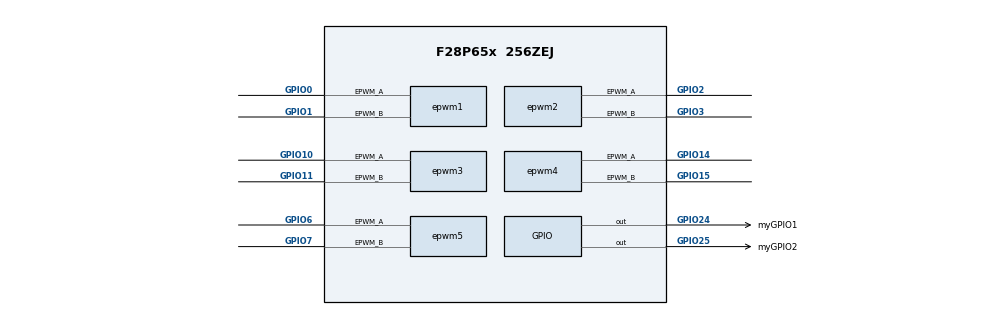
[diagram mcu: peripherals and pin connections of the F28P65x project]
/**
 * @cliArgs --device "F28P65x" --package "256ZEJ" --part "F28P65x_256ZEJ" --context "CPU1" --product "C2000WARE@5.00.00.00"
 * @versions {"tool":"1.17.0+3047"}
 */

/**
 * Import the modules used in this configuration.
 */
const epwm   = scripting.addModule("/driverlib/epwm.js", {}, false);
const epwm1  = epwm.addInstance();
const epwm2  = epwm.addInstance();
const epwm3  = epwm.addInstance();
const epwm4  = epwm.addInstance();
const epwm5  = epwm.addInstance();
const gpio   = scripting.addModule("/driverlib/gpio.js", {}, false);
const gpio1  = gpio.addInstance();
const gpio2  = gpio.addInstance();
const sysctl = scripting.addModule("/driverlib/sysctl.js");

/**
 * Write custom configuration values to the imported modules.
 */
epwm1.epwmTimebase_counterMode                                 = "EPWM_COUNTER_MODE_UP";
epwm1.epwmTimebase_syncOutPulseMode                            = ["EPWM_SYNC_OUT_PULSE_ON_ALL"];
epwm1.epwmActionQualifier_EPWM_AQ_OUTPUT_A_ON_TIMEBASE_UP_CMPA = "EPWM_AQ_OUTPUT_LOW";
epwm1.epwmTimebase_periodLoadMode                              = "EPWM_PERIOD_DIRECT_LOAD";
epwm1.epwmCounterCompare_shadowLoadModeCMPD                    = "EPWM_COMP_LOAD_ON_CNTR_PERIOD";
epwm1.hrpwm_edgeModeA                                          = "HRPWM_MEP_CTRL_RISING_EDGE";
epwm1.epwmXCMP_enable                                          = true;
epwm1.XCMPA_ACTIVE_OUTPUT_ON_TIMEBASE_XCMP1                    = "EPWM_AQ_OUTPUT_HIGH";
epwm1.XCMPA_ACTIVE_OUTPUT_ON_TIMEBASE_XCMP2                    = "EPWM_AQ_OUTPUT_LOW";
epwm1.epwmTimebase_period                                      = 1999;
epwm1.epwmXCMP_setRegisters_XTBPRD                             = 1999;
epwm1.epwmXCMP_selectAllocationXCMPA_NoSplitorSplit            = "EPWM_XCMP_8_CMPA";
epwm1.epwmXCMP_setXCMPA_XCMP3_ACTIVE                           = 500;
epwm1.epwmXCMP_setXCMPA_XCMP4_ACTIVE                           = 750;
epwm1.epwmXCMP_setXCMPA_XCMP5_ACTIVE                           = 1000;
epwm1.epwmXCMP_setXCMPA_XCMP6_ACTIVE                           = 1250;
epwm1.epwmXCMP_setXCMPA_XCMP7_ACTIVE                           = 1500;
epwm1.epwmXCMP_setXCMPA_XCMP8_ACTIVE                           = 1750;
epwm1.XCMPA_ACTIVE_OUTPUT_ON_TIMEBASE_XCMP3                    = "EPWM_AQ_OUTPUT_HIGH";
epwm1.XCMPA_ACTIVE_OUTPUT_ON_TIMEBASE_XCMP4                    = "EPWM_AQ_OUTPUT_LOW";
epwm1.XCMPA_ACTIVE_OUTPUT_ON_TIMEBASE_XCMP5                    = "EPWM_AQ_OUTPUT_HIGH";
epwm1.XCMPA_ACTIVE_OUTPUT_ON_TIMEBASE_XCMP6                    = "EPWM_AQ_OUTPUT_LOW";
epwm1.XCMPA_ACTIVE_OUTPUT_ON_TIMEBASE_XCMP7                    = "EPWM_AQ_OUTPUT_HIGH";
epwm1.XCMPA_ACTIVE_OUTPUT_ON_TIMEBASE_XCMP8                    = "EPWM_AQ_OUTPUT_LOW";
epwm1.epwmICL_A_OUTHIGH                                        = ["EPWM_MINDB_ICL_LUT_DEC0","EPWM_MINDB_ICL_LUT_DEC1","EPWM_MINDB_ICL_LUT_DEC2","EPWM_MINDB_ICL_LUT_DEC3"];
epwm1.epwmICL_A_OUTLOW                                         = ["EPWM_MINDB_ICL_LUT_DEC4","EPWM_MINDB_ICL_LUT_DEC5","EPWM_MINDB_ICL_LUT_DEC6","EPWM_MINDB_ICL_LUT_DEC7"];
epwm1.epwmTimebase_syncInPulseSource                           = "EPWM_SYNC_IN_PULSE_SRC_DISABLE";
epwm1.epwmCounterCompare_shadowLoadModeCMPC                    = "EPWM_COMP_LOAD_ON_CNTR_PERIOD";
epwm1.epwmXCMP_setXCMPA_XCMP2_ACTIVE                           = 250;
epwm1.$name                                                    = "myEPWM1";
epwm1.epwm.$assign                                             = "EPWM1";
epwm1.epwm.epwm_aPin.$assign                                   = "GPIO0";
epwm1.epwm.epwm_bPin.$assign                                   = "GPIO1";
scripting.suppress("When XCMP mode is enabled, EPWM Time Base Period will be set within XCMP Mode", epwm1, "epwmTimebase_period");

epwm2.copyFrom                                                 = "myEPWM0";
epwm2.epwmTimebase_periodLoadMode                              = "EPWM_PERIOD_DIRECT_LOAD";
epwm2.epwmTimebase_period                                      = 1999;
epwm2.epwmTimebase_counterMode                                 = "EPWM_COUNTER_MODE_UP";
epwm2.epwmTimebase_syncInPulseSource                           = "EPWM_SYNC_IN_PULSE_SRC_DISABLE";
epwm2.epwmTimebase_syncOutPulseMode                            = ["EPWM_SYNC_OUT_PULSE_ON_ALL"];
epwm2.epwmCounterCompare_shadowLoadModeCMPC                    = "EPWM_COMP_LOAD_ON_CNTR_PERIOD";
epwm2.epwmCounterCompare_shadowLoadModeCMPD                    = "EPWM_COMP_LOAD_ON_CNTR_PERIOD";
epwm2.epwmActionQualifier_EPWM_AQ_OUTPUT_A_ON_TIMEBASE_UP_CMPA = "EPWM_AQ_OUTPUT_LOW";
epwm2.epwmICL_A_OUTHIGH                                        = ["EPWM_MINDB_ICL_LUT_DEC0","EPWM_MINDB_ICL_LUT_DEC1","EPWM_MINDB_ICL_LUT_DEC2","EPWM_MINDB_ICL_LUT_DEC3"];
epwm2.epwmICL_A_OUTLOW                                         = ["EPWM_MINDB_ICL_LUT_DEC4","EPWM_MINDB_ICL_LUT_DEC5","EPWM_MINDB_ICL_LUT_DEC6","EPWM_MINDB_ICL_LUT_DEC7"];
epwm2.hrpwm_edgeModeA                                          = "HRPWM_MEP_CTRL_RISING_EDGE";
epwm2.epwmXCMP_enable                                          = true;
epwm2.epwmXCMP_RegisterSplit_enable                            = true;
epwm2.epwmXCMP_selectAllocationXCMPA_NoSplitorSplit            = "EPWM_XCMP_4_CMPA";
epwm2.epwmXCMP_setXCMPA_XCMP2_ACTIVE                           = 500;
epwm2.epwmXCMP_setXCMPA_XCMP4_ACTIVE                           = 1500;
epwm2.epwmXCMP_setXCMPA_XCMP3_ACTIVE                           = 1000;
epwm2.epwmXCMP_selectAllocationXCMPB_Split                     = "EPWM_XCMP_8_CMPB";
epwm2.epwmXCMP_setXCMPB_XCMP6_ACTIVE                           = 500;
epwm2.epwmXCMP_setXCMPB_XCMP7_ACTIVE                           = 1000;
epwm2.epwmXCMP_setXCMPB_XCMP8_ACTIVE                           = 1500;
epwm2.epwmXCMP_setRegisters_XTBPRD                             = 1999;
epwm2.XCMPA_ACTIVE_OUTPUT_ON_TIMEBASE_XCMP1                    = "EPWM_AQ_OUTPUT_HIGH";
epwm2.XCMPA_ACTIVE_OUTPUT_ON_TIMEBASE_XCMP2                    = "EPWM_AQ_OUTPUT_LOW";
epwm2.XCMPA_ACTIVE_OUTPUT_ON_TIMEBASE_XCMP3                    = "EPWM_AQ_OUTPUT_HIGH";
epwm2.XCMPA_ACTIVE_OUTPUT_ON_TIMEBASE_XCMP4                    = "EPWM_AQ_OUTPUT_LOW";
epwm2.XCMPB_ACTIVE_OUTPUT_ON_TIMEBASE_XCMP5                    = "EPWM_AQ_OUTPUT_LOW";
epwm2.XCMPB_ACTIVE_OUTPUT_ON_TIMEBASE_XCMP6                    = "EPWM_AQ_OUTPUT_HIGH";
epwm2.XCMPB_ACTIVE_OUTPUT_ON_TIMEBASE_XCMP7                    = "EPWM_AQ_OUTPUT_LOW";
epwm2.XCMPB_ACTIVE_OUTPUT_ON_TIMEBASE_XCMP8                    = "EPWM_AQ_OUTPUT_HIGH";
epwm2.$name                                                    = "myEPWM2";
epwm2.epwm.$assign                                             = "EPWM2";
epwm2.epwm.epwm_aPin.$assign                                   = "GPIO2";
epwm2.epwm.epwm_bPin.$assign                                   = "GPIO3";

epwm3.epwmTimebase_counterMode                        = "EPWM_COUNTER_MODE_UP";
epwm3.epwmTimebase_period                             = 1999;
epwm3.epwmTimebase_syncOutPulseMode                   = ["EPWM_SYNC_OUT_PULSE_ON_ALL"];
epwm3.epwmTimebase_syncInPulseSource                  = "EPWM_SYNC_IN_PULSE_SRC_DISABLE";
epwm3.epwmXCMP_enable                                 = true;
epwm3.epwmCounterCompare_shadowLoadModeCMPC           = "EPWM_COMP_LOAD_ON_CNTR_PERIOD";
epwm3.epwmCounterCompare_shadowLoadModeCMPD           = "EPWM_COMP_LOAD_ON_CNTR_PERIOD";
epwm3.epwmXCMP_selectNumberShadowRegisterLevels       = "EPWM_XCMP_XLOADCTL_SHDWLEVEL_3";
epwm3.epwmXCMP_selectLoadMode                         = "EPWM_XCMP_XLOADCTL_LOADMODE_LOADMULTIPLE";
epwm3.epwmXCMP_selectAllocationXCMPA_NoSplitorSplit   = "EPWM_XCMP_4_CMPA";
epwm3.epwmXCMP_selectRepeatCountShadowRegisterLevel3  = "4";
epwm3.epwmXCMP_selectRepeatCountShadowRegisterLevel2  = "2";
epwm3.epwmXCMP_setRegisters_XTBPRD                    = 1999;
epwm3.epwmXCMP_setXCMPA_XCMP2_SHADOW3                 = 500;
epwm3.epwmXCMP_setXCMPA_XCMP3_SHADOW3                 = 1000;
epwm3.epwmXCMP_setXCMPA_XCMP4_SHADOW3                 = 1500;
epwm3.epwmXCMP_setXCMPA_XCMP2_SHADOW2                 = 500;
epwm3.epwmXCMP_setXCMPA_XCMP3_SHADOW2                 = 1000;
epwm3.epwmXCMP_setXCMPA_XCMP4_SHADOW2                 = 1500;
epwm3.epwmXCMP_setXCMPA_XCMP2_SHADOW1                 = 500;
epwm3.epwmXCMP_setXCMPA_XCMP3_SHADOW1                 = 1000;
epwm3.epwmXCMP_setXCMPA_XCMP4_SHADOW1                 = 1500;
epwm3.XCMPA_SHADOW1_OUTPUT_ON_TIMEBASE_XCMP1          = "EPWM_AQ_OUTPUT_HIGH";
epwm3.XCMPA_SHADOW1_OUTPUT_ON_TIMEBASE_XCMP2          = "EPWM_AQ_OUTPUT_LOW";
epwm3.XCMPA_SHADOW1_OUTPUT_ON_TIMEBASE_XCMP3          = "EPWM_AQ_OUTPUT_HIGH";
epwm3.XCMPA_SHADOW1_OUTPUT_ON_TIMEBASE_XCMP4          = "EPWM_AQ_OUTPUT_LOW";
epwm3.XCMPA_SHADOW2_OUTPUT_ON_TIMEBASE_XCMP1          = "EPWM_AQ_OUTPUT_HIGH";
epwm3.XCMPA_SHADOW2_OUTPUT_ON_TIMEBASE_XCMP2          = "EPWM_AQ_OUTPUT_LOW";
epwm3.XCMPA_SHADOW2_OUTPUT_ON_TIMEBASE_XCMP3          = "EPWM_AQ_OUTPUT_HIGH";
epwm3.XCMPA_SHADOW2_OUTPUT_ON_TIMEBASE_XCMP4          = "EPWM_AQ_OUTPUT_LOW";
epwm3.XCMPA_SHADOW3_OUTPUT_ON_TIMEBASE_XCMP1          = "EPWM_AQ_OUTPUT_HIGH";
epwm3.XCMPA_SHADOW3_OUTPUT_ON_TIMEBASE_XCMP2          = "EPWM_AQ_OUTPUT_LOW";
epwm3.XCMPA_SHADOW3_OUTPUT_ON_TIMEBASE_XCMP3          = "EPWM_AQ_OUTPUT_HIGH";
epwm3.XCMPA_SHADOW3_OUTPUT_ON_TIMEBASE_XCMP4          = "EPWM_AQ_OUTPUT_LOW";
epwm3.epwmEventTrigger_enableInterrupt                = true;
epwm3.epwmEventTrigger_registerInterrupts             = true;
epwm3.epwmEventTrigger_interruptSource                = "EPWM_INT_TBCTR_ZERO";
epwm3.epwmEventTrigger_interruptEventCount            = "1";
epwm3.epwmXCMP_RegisterLoad_enable                    = true;
epwm3.epwmXCMP_setShadowRegisters1_XTBPRD             = 1999;
epwm3.epwmXCMP_setShadowRegisters2_XTBPRD             = 1999;
epwm3.epwmXCMP_setShadowRegisters3_XTBPRD             = 1999;
epwm3.epwmActionQualifier_EPWM_AQ_OUTPUT_A_shadowMode = true;
epwm3.epwmActionQualifier_EPWM_AQ_OUTPUT_B_shadowMode = true;
epwm3.$name                                           = "myEPWM6";
epwm3.epwm.$assign                                    = "EPWM6";
epwm3.epwm.epwm_aPin.$assign                          = "GPIO10";
epwm3.epwm.epwm_bPin.$assign                          = "GPIO11";
epwm3.epwmInt.enableInterrupt                         = true;
epwm3.epwmInt.interruptHandler                        = "epwm6_ISR";

epwm4.epwmTimebase_counterMode                      = "EPWM_COUNTER_MODE_UP";
epwm4.epwmTimebase_syncInPulseSource                = "EPWM_SYNC_IN_PULSE_SRC_DISABLE";
epwm4.epwmCounterCompare_shadowLoadModeCMPC         = "EPWM_COMP_LOAD_ON_CNTR_PERIOD";
epwm4.epwmCounterCompare_shadowLoadModeCMPD         = "EPWM_COMP_LOAD_ON_CNTR_PERIOD";
epwm4.epwmXCMP_enable                               = true;
epwm4.epwmXCMP_selectNumberShadowRegisterLevels     = "EPWM_XCMP_XLOADCTL_SHDWLEVEL_3";
epwm4.epwmXCMP_RegisterLoad_enable                  = true;
epwm4.epwmXCMP_selectShadowRegisterLevelLoad        = "EPWM_XCMP_XLOADCTL_SHDWBUFPTR_THREE";
epwm4.epwmXCMP_selectAllocationXCMPA_NoSplitorSplit = "EPWM_XCMP_4_CMPA";
epwm4.epwmXCMP_setXCMPA_XCMP2_SHADOW3               = 500;
epwm4.epwmXCMP_setXCMPA_XCMP3_SHADOW3               = 1000;
epwm4.epwmXCMP_setXCMPA_XCMP4_SHADOW3               = 1500;
epwm4.epwmXCMP_setRegisters_XTBPRD                  = 1999;
epwm4.epwmXCMP_setShadowRegisters3_XTBPRD           = 1999;
epwm4.XCMPA_SHADOW3_OUTPUT_ON_TIMEBASE_XCMP1        = "EPWM_AQ_OUTPUT_HIGH";
epwm4.XCMPA_SHADOW3_OUTPUT_ON_TIMEBASE_XCMP2        = "EPWM_AQ_OUTPUT_LOW";
epwm4.XCMPA_SHADOW3_OUTPUT_ON_TIMEBASE_XCMP3        = "EPWM_AQ_OUTPUT_HIGH";
epwm4.XCMPA_SHADOW3_OUTPUT_ON_TIMEBASE_XCMP4        = "EPWM_AQ_OUTPUT_LOW";
epwm4.epwmEventTrigger_enableInterrupt              = true;
epwm4.epwmEventTrigger_registerInterrupts           = true;
epwm4.epwmEventTrigger_interruptSource              = "EPWM_INT_TBCTR_ZERO";
epwm4.epwmEventTrigger_interruptEventCount          = "1";
epwm4.$name                                         = "myEPWM8";
epwm4.epwm.$assign                                  = "EPWM8";
epwm4.epwm.epwm_aPin.$assign                        = "GPIO14";
epwm4.epwm.epwm_bPin.$assign                        = "GPIO15";
epwm4.epwmInt.enableInterrupt                       = true;
epwm4.epwmInt.interruptHandler                      = "epwm8_ISR";

epwm5.$name                                                    = "myEPWM4";
epwm5.copyFrom                                                 = "myEPWM0";
epwm5.epwmTimebase_periodLoadMode                              = "EPWM_PERIOD_DIRECT_LOAD";
epwm5.epwmTimebase_period                                      = 1999;
epwm5.epwmTimebase_counterMode                                 = "EPWM_COUNTER_MODE_UP";
epwm5.epwmTimebase_syncInPulseSource                           = "EPWM_SYNC_IN_PULSE_SRC_DISABLE";
epwm5.epwmTimebase_syncOutPulseMode                            = ["EPWM_SYNC_OUT_PULSE_ON_ALL"];
epwm5.epwmCounterCompare_shadowLoadModeCMPC                    = "EPWM_COMP_LOAD_ON_CNTR_PERIOD";
epwm5.epwmCounterCompare_shadowLoadModeCMPD                    = "EPWM_COMP_LOAD_ON_CNTR_PERIOD";
epwm5.epwmActionQualifier_EPWM_AQ_OUTPUT_A_ON_TIMEBASE_UP_CMPA = "EPWM_AQ_OUTPUT_LOW";
epwm5.epwmICL_A_OUTHIGH                                        = ["EPWM_MINDB_ICL_LUT_DEC0","EPWM_MINDB_ICL_LUT_DEC1","EPWM_MINDB_ICL_LUT_DEC2","EPWM_MINDB_ICL_LUT_DEC3"];
epwm5.epwmICL_A_OUTLOW                                         = ["EPWM_MINDB_ICL_LUT_DEC4","EPWM_MINDB_ICL_LUT_DEC5","EPWM_MINDB_ICL_LUT_DEC6","EPWM_MINDB_ICL_LUT_DEC7"];
epwm5.hrpwm_edgeModeA                                          = "HRPWM_MEP_CTRL_RISING_EDGE";
epwm5.epwmXCMP_enable                                          = true;
epwm5.epwmXCMP_RegisterSplit_enable                            = true;
epwm5.epwmXCMP_selectAllocationXCMPA_NoSplitorSplit            = "EPWM_XCMP_4_CMPA";
epwm5.epwmXCMP_setXCMPA_XCMP2_ACTIVE                           = 500;
epwm5.epwmXCMP_setXCMPA_XCMP4_ACTIVE                           = 1500;
epwm5.epwmXCMP_setXCMPA_XCMP3_ACTIVE                           = 1000;
epwm5.epwmXCMP_selectAllocationXCMPB_Split                     = "EPWM_XCMP_8_CMPB";
epwm5.epwmXCMP_setXCMPB_XCMP6_ACTIVE                           = 500;
epwm5.epwmXCMP_setXCMPB_XCMP7_ACTIVE                           = 1000;
epwm5.epwmXCMP_setXCMPB_XCMP8_ACTIVE                           = 1500;
epwm5.epwmXCMP_setRegisters_XTBPRD                             = 1999;
epwm5.XCMPA_ACTIVE_OUTPUT_ON_TIMEBASE_XCMP1                    = "EPWM_AQ_OUTPUT_HIGH";
epwm5.XCMPA_ACTIVE_OUTPUT_ON_TIMEBASE_XCMP2                    = "EPWM_AQ_OUTPUT_LOW";
epwm5.XCMPA_ACTIVE_OUTPUT_ON_TIMEBASE_XCMP3                    = "EPWM_AQ_OUTPUT_HIGH";
epwm5.XCMPA_ACTIVE_OUTPUT_ON_TIMEBASE_XCMP4                    = "EPWM_AQ_OUTPUT_LOW";
epwm5.XCMPB_ACTIVE_OUTPUT_ON_TIMEBASE_XCMP5                    = "EPWM_AQ_OUTPUT_LOW";
epwm5.XCMPB_ACTIVE_OUTPUT_ON_TIMEBASE_XCMP6                    = "EPWM_AQ_OUTPUT_HIGH";
epwm5.XCMPB_ACTIVE_OUTPUT_ON_TIMEBASE_XCMP7                    = "EPWM_AQ_OUTPUT_LOW";
epwm5.XCMPB_ACTIVE_OUTPUT_ON_TIMEBASE_XCMP8                    = "EPWM_AQ_OUTPUT_HIGH";
epwm5.epwmMinDeadBand_EnableA                                  = true;
epwm5.epwmMinDeadBand_EnableB                                  = true;
epwm5.epwmMinDeadBand_A_setDelay                               = 200;
epwm5.epwmMinDeadBand_A_configBlockSignal                      = "EPWM_MINDB_BLOCKING_SIGNAL_SWAPBLOCK";
epwm5.epwmMinDeadBand_B_setDelay                               = 200;
epwm5.epwmMinDeadBand_B_configBlockSignal                      = "EPWM_MINDB_BLOCKING_SIGNAL_SWAPBLOCK";
epwm5.epwm.$assign                                             = "EPWM4";
epwm5.epwm.epwm_aPin.$assign                                   = "GPIO6";
epwm5.epwm.epwm_bPin.$assign                                   = "GPIO7";

gpio1.direction       = "GPIO_DIR_MODE_OUT";
gpio1.$name           = "myGPIO1";
gpio1.gpioPin.$assign = "GPIO24";

gpio2.direction       = "GPIO_DIR_MODE_OUT";
gpio2.$name           = "myGPIO2";
gpio2.gpioPin.$assign = "GPIO25";
